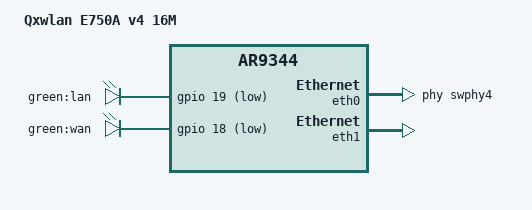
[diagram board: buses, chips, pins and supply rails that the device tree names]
// SPDX-License-Identifier: GPL-2.0-or-later OR MIT

#include "ar9344_qxwlan_e750x.dtsi"

/ {
	model = "Qxwlan E750A v4 16M";
	compatible = "qxwlan,e750a-v4-16m", "qca,ar9344";
};

&leds {
	lan {
		label = "green:lan";
		gpios = <&gpio 19 GPIO_ACTIVE_LOW>;
	};

	wan {
		label = "green:wan";
		gpios = <&gpio 18 GPIO_ACTIVE_LOW>;
	};
};

&eth0 {
	status = "okay";

	phy-handle = <&swphy4>;

	nvmem-cells = <&macaddr_pridata_400>;
	nvmem-cell-names = "mac-address";
	mac-address-increment = <1>;
};

&eth1 {
	status = "okay";

	nvmem-cells = <&macaddr_pridata_400>;
	nvmem-cell-names = "mac-address";

	gmac-config {
		device = <&gmac>;
		switch-phy-swap = <0>;
		switch-only-mode = <1>;
	};
};

&partitions {
	partition@70000 {
		compatible = "denx,uimage";
		label = "firmware";
		reg = <0x070000 0xf90000>;
	};
};

&pridata {
	compatible = "nvmem-cells";
	#address-cells = <1>;
	#size-cells = <1>;

	macaddr_pridata_400: macaddr@400 {
		reg = <0x400 0x6>;
	};
};
